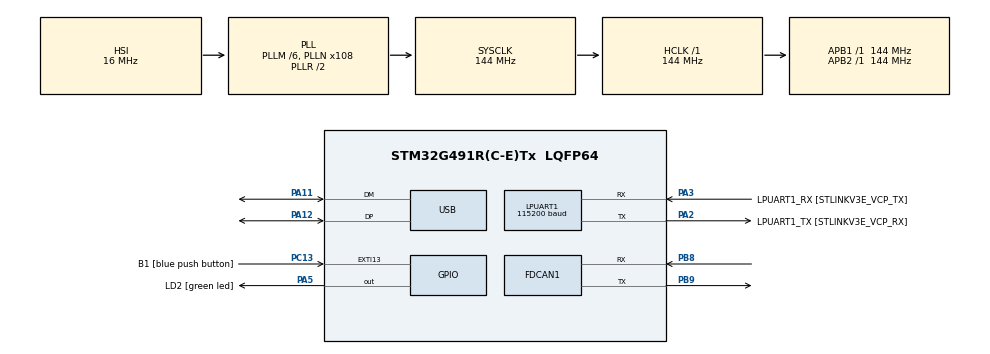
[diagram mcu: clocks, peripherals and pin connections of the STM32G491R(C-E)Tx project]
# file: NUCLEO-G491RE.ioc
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FDCAN1.AutoRetransmission=DISABLE
FDCAN1.CalculateBaudRateNominal=1000000
FDCAN1.CalculateTimeBitNominal=1000
FDCAN1.CalculateTimeQuantumNominal=62.5
FDCAN1.DataPrescaler=3
FDCAN1.DataTimeSeg1=13
FDCAN1.DataTimeSeg2=2
FDCAN1.NominalPrescaler=3
FDCAN1.NominalTimeSeg1=13
FDCAN1.NominalTimeSeg2=2
LPUART1.BaudRate=115200
LPUART1.WordLength=UART_WORDLENGTH_8B
Mcu.Family=STM32G4
Mcu.Name=STM32G491R(C-E)Tx
Mcu.Package=LQFP64
NVIC.EXTI15_10_IRQn=true\:0\:0\:false\:false\:true\:true\:true\:true
NVIC.FDCAN1_IT0_IRQn=true\:0\:0\:false\:false\:true\:true\:true\:true
NVIC.PriorityGroup=NVIC_PRIORITYGROUP_4
NVIC.USB_LP_IRQn=true\:0\:0\:false\:false\:true\:false\:true\:true
PA11.Mode=Device
PA11.Signal=USB_DM
PA12.Mode=Device
PA12.Signal=USB_DP
PA13.GPIO_Label=T_SWDIO
PA13.Mode=Serial_Wire
PA13.Signal=SYS_JTMS-SWDIO
PA14.GPIO_Label=T_SWCLK
PA14.Mode=Serial_Wire
PA14.Signal=SYS_JTCK-SWCLK
PA2.GPIO_Label=LPUART1_TX [STLINKV3E_VCP_RX]
PA2.Mode=Asynchronous
PA2.Signal=LPUART1_TX
PA3.GPIO_Label=LPUART1_RX [STLINKV3E_VCP_TX]
PA3.Mode=Asynchronous
PA3.Signal=LPUART1_RX
PA5.GPIO_Label=LD2 [green led]
PA5.Signal=GPIO_Output
PB3.GPIO_Label=T_SWO
PB3.Signal=SYS_JTDO-SWO
PB8-BOOT0.Mode=FDCAN_Activate
PB8-BOOT0.Signal=FDCAN1_RX
PB9.Mode=FDCAN_Activate
PB9.Signal=FDCAN1_TX
PC13.GPIO_Label=B1 [blue push button]
PC13.Signal=GPXTI13
PC14-OSC32_IN.Mode=LSE-External-Oscillator
PC14-OSC32_IN.Signal=RCC_OSC32_IN
PC15-OSC32_OUT.Mode=LSE-External-Oscillator
PC15-OSC32_OUT.Signal=RCC_OSC32_OUT
PF0-OSC_IN.Mode=HSE-External-Oscillator
PF0-OSC_IN.Signal=RCC_OSC_IN
PF1-OSC_OUT.Mode=HSE-External-Oscillator
PF1-OSC_OUT.Signal=RCC_OSC_OUT
ProjectManager.HeapSize=0x200
ProjectManager.StackSize=0x400
ProjectManager.TargetToolchain=Makefile
RCC.ADC12Freq_Value=144000000
RCC.ADC345Freq_Value=144000000
RCC.AHBFreq_Value=144000000
RCC.APB1Freq_Value=144000000
RCC.APB1TimFreq_Value=144000000
RCC.APB2Freq_Value=144000000
RCC.APB2TimFreq_Value=144000000
RCC.CK48CLockSelection=RCC_USBCLKSOURCE_PLL
RCC.CortexFreq_Value=144000000
RCC.EXTERNAL_CLOCK_VALUE=12288000
RCC.FDCANCLockSelection=RCC_FDCANCLKSOURCE_PLL
RCC.HCLKFreq_Value=144000000
RCC.HSE_VALUE=24000000
RCC.HSI48_VALUE=48000000
RCC.HSI_VALUE=16000000
RCC.PLLM=RCC_PLLM_DIV6
RCC.PLLN=108
RCC.PLLQ=RCC_PLLQ_DIV6
RCC.RTCClockSelection=RCC_RTCCLKSOURCE_LSE
RCC.SYSCLKFreq_VALUE=144000000
RCC.SYSCLKSource=RCC_SYSCLKSOURCE_PLLCLK
RCC.USBFreq_Value=48000000
RCC.VCOOutputFreq_Value=288000000
USB_DEVICE.CLASS_NAME_FS=CDC
USB_DEVICE.VirtualMode=Cdc
USB_DEVICE.VirtualModeFS=Cdc_FS
VP_SYS_VS_DBSignals.Mode=DisableDeadBatterySignals
VP_USB_DEVICE_VS_USB_DEVICE_CDC_FS.Mode=CDC_FS
board=NUCLEO-G491RE

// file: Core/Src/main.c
/* USER CODE BEGIN Header */
/**
 ******************************************************************************
 * @file           : main.c
 * @brief          : Main program body
 ******************************************************************************
 * @attention
 *
 * Copyright (c) 2023 STMicroelectronics.
 * All rights reserved.
 *
 * This software is licensed under terms that can be found in the LICENSE file
 * in the root directory of this software component.
 * If no LICENSE file comes with this software, it is provided AS-IS.
 *
 ******************************************************************************
 */
/* USER CODE END Header */
#include "main.h"
#include "fdcan.h"
#include "usart.h"
#include "usb_device.h"
#include "gpio.h"

/* USER CODE BEGIN Includes */
#include "BootloaderTools.h"
#include "cppMain.h"
/* USER CODE END Includes */

void SystemClock_Config(void);
/* USER CODE BEGIN PFP */
#define PUTCHAR_PROTOTYPE int __io_putchar(int ch)
/* USER CODE END PFP */

int main(void)
{
  /* USER CODE BEGIN 1 */

  checkAndGoToBootloader();

  // Turn off buffers, so I/O occurs immediately
  setvbuf(stdin, NULL, _IONBF, 0);
  setvbuf(stdout, NULL, _IONBF, 0);
  setvbuf(stderr, NULL, _IONBF, 0);
  /* USER CODE END 1 */

  /* MCU Configuration--------------------------------------------------------*/

  /* Reset of all peripherals, Initializes the Flash interface and the Systick. */
  HAL_Init();

  /* Configure the system clock */
  SystemClock_Config();

  /* Initialize all configured peripherals */
  MX_GPIO_Init();
  MX_LPUART1_UART_Init();
  MX_USB_Device_Init();
  MX_FDCAN1_Init();
  /* USER CODE BEGIN 2 */
  cppMain();
  /* USER CODE END 2 */

  /* Infinite loop */
    while (1) {

    }
}

void SystemClock_Config(void)
{
  RCC_OscInitTypeDef RCC_OscInitStruct = {0};
  RCC_ClkInitTypeDef RCC_ClkInitStruct = {0};

  /** Configure the main internal regulator output voltage
  */
  HAL_PWREx_ControlVoltageScaling(PWR_REGULATOR_VOLTAGE_SCALE1);

  /** Initializes the RCC Oscillators according to the specified parameters
  * in the RCC_OscInitTypeDef structure.
  */
  RCC_OscInitStruct.OscillatorType = RCC_OSCILLATORTYPE_HSI;
  RCC_OscInitStruct.HSIState = RCC_HSI_ON;
  RCC_OscInitStruct.HSICalibrationValue = RCC_HSICALIBRATION_DEFAULT;
  RCC_OscInitStruct.PLL.PLLState = RCC_PLL_ON;
  RCC_OscInitStruct.PLL.PLLSource = RCC_PLLSOURCE_HSI;
  RCC_OscInitStruct.PLL.PLLM = RCC_PLLM_DIV6;
  RCC_OscInitStruct.PLL.PLLN = 108;
  RCC_OscInitStruct.PLL.PLLP = RCC_PLLP_DIV2;
  RCC_OscInitStruct.PLL.PLLQ = RCC_PLLQ_DIV6;
  RCC_OscInitStruct.PLL.PLLR = RCC_PLLR_DIV2;
  if (HAL_RCC_OscConfig(&RCC_OscInitStruct) != HAL_OK)
  {
    Error_Handler();
  }

  /** Initializes the CPU, AHB and APB buses clocks
  */
  RCC_ClkInitStruct.ClockType = RCC_CLOCKTYPE_HCLK|RCC_CLOCKTYPE_SYSCLK
                              |RCC_CLOCKTYPE_PCLK1|RCC_CLOCKTYPE_PCLK2;
  RCC_ClkInitStruct.SYSCLKSource = RCC_SYSCLKSOURCE_PLLCLK;
  RCC_ClkInitStruct.AHBCLKDivider = RCC_SYSCLK_DIV1;
  RCC_ClkInitStruct.APB1CLKDivider = RCC_HCLK_DIV1;
  RCC_ClkInitStruct.APB2CLKDivider = RCC_HCLK_DIV1;

  if (HAL_RCC_ClockConfig(&RCC_ClkInitStruct, FLASH_LATENCY_4) != HAL_OK)
  {
    Error_Handler();
  }
}

/* USER CODE BEGIN 4 */
// PUTCHAR_PROTOTYPE
// {
//   HAL_UART_Transmit(&hlpuart1, (uint8_t*)&ch, 1, 0xFFFF);
//   return ch;
// }

// int _write(int file, char* ptr, int len)
// {
//   int DataIdx;

//   for (DataIdx = 0; DataIdx < len; DataIdx++) {
//     __io_putchar(*ptr++);
//   }
//   return len;
// }
/* USER CODE END 4 */

void Error_Handler(void)
{
    __disable_irq();
    while (1) {
    }
}
